# TM4C123GH6PM register map
Vendor: Texas Instruments; Series: TM4C; File version: 11073
CPU: CM4 r1p2, little endian, MPU, FPU, 3 interrupt priority bits
Registers are 32-bit, read-write, reset 0x1 unless marked. A register's access mark holds for its fields unless they carry their own. Offsets are from the block's base; [hi:lo] are bit positions.

## I2C0 — Register map for I2C0 peripheral
Base 0x40020000; register names take the prefix I2C0
Same registers: I2C1 0x40021000 (register names take the prefix I2C1), I2C2 0x40022000 (register names take the prefix I2C2), I2C3 0x40023000 (register names take the prefix I2C3)
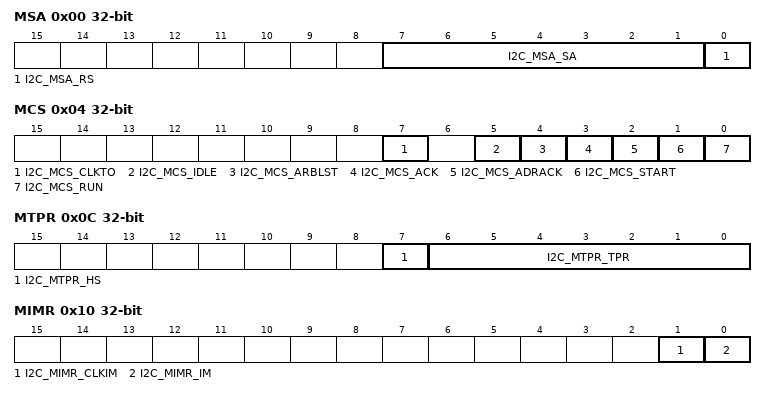
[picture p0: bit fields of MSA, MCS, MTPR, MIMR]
0x00 MSA (reset mask 0x0) — I2C Master Slave Address
  [7:1] I2C_MSA_SA — I2C Slave Address
  [0] I2C_MSA_RS — Receive not send
0x04 MCS (reset mask 0x0) — I2C Master Control/Status
  [7] I2C_MCS_CLKTO — Clock Timeout Error
  [5] I2C_MCS_IDLE — I2C Idle
  [4] I2C_MCS_ARBLST — Arbitration Lost
  [3] I2C_MCS_ACK — Data Acknowledge Enable
  [2] I2C_MCS_ADRACK — Acknowledge Address
  [1] I2C_MCS_START — Generate START
  [0] I2C_MCS_RUN — I2C Master Enable
0x04 MCS (reset mask 0x0) (I2C0_ALT view) — I2C Master Control/Status
  [6] I2C_MCS_BUSBSY — Bus Busy
  [4] I2C_MCS_HS — High-Speed Enable
  [3] I2C_MCS_DATACK — Acknowledge Data
  [2] I2C_MCS_STOP — Generate STOP
  [1] I2C_MCS_ERROR — Error
  [0] I2C_MCS_BUSY — I2C Busy
0x08 MDR (reset mask 0x0) — I2C Master Data
  [7:0] I2C_MDR_DATA — Data Transferred
0x0C MTPR (reset mask 0x0) — I2C Master Timer Period
  [7] I2C_MTPR_HS — High-Speed Enable
  [6:0] I2C_MTPR_TPR — Timer Period
0x10 MIMR (reset mask 0x0) — I2C Master Interrupt Mask
  [1] I2C_MIMR_CLKIM — Clock Timeout Interrupt Mask
  [0] I2C_MIMR_IM — Master Interrupt Mask
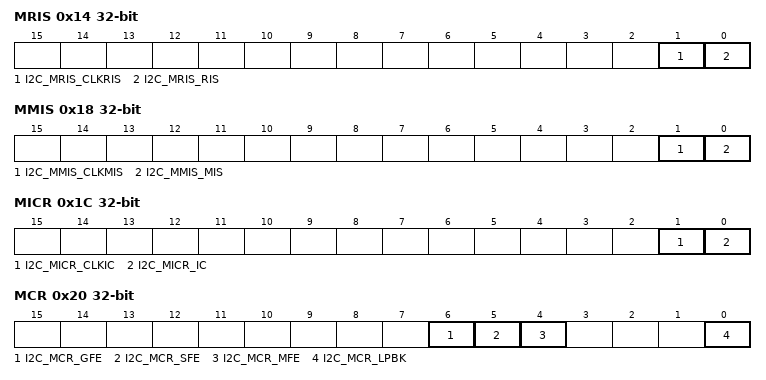
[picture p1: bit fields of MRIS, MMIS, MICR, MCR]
0x14 MRIS (reset mask 0x0) — I2C Master Raw Interrupt Status
  [1] I2C_MRIS_CLKRIS — Clock Timeout Raw Interrupt Status
  [0] I2C_MRIS_RIS — Master Raw Interrupt Status
0x18 MMIS (reset mask 0x0) — I2C Master Masked Interrupt Status
  [1] I2C_MMIS_CLKMIS — Clock Timeout Masked Interrupt Status
  [0] I2C_MMIS_MIS — Masked Interrupt Status
0x1C MICR wo (reset mask 0x0) — I2C Master Interrupt Clear
  [1] I2C_MICR_CLKIC — Clock Timeout Interrupt Clear
  [0] I2C_MICR_IC — Master Interrupt Clear
0x20 MCR (reset mask 0x0) — I2C Master Configuration
  [6] I2C_MCR_GFE — I2C Glitch Filter Enable
  [5] I2C_MCR_SFE — I2C Slave Function Enable
  [4] I2C_MCR_MFE — I2C Master Function Enable
  [0] I2C_MCR_LPBK — I2C Loopback
0x24 MCLKOCNT (reset mask 0x0) — I2C Master Clock Low Timeout Count
  [7:0] I2C_MCLKOCNT_CNTL — I2C Master Count
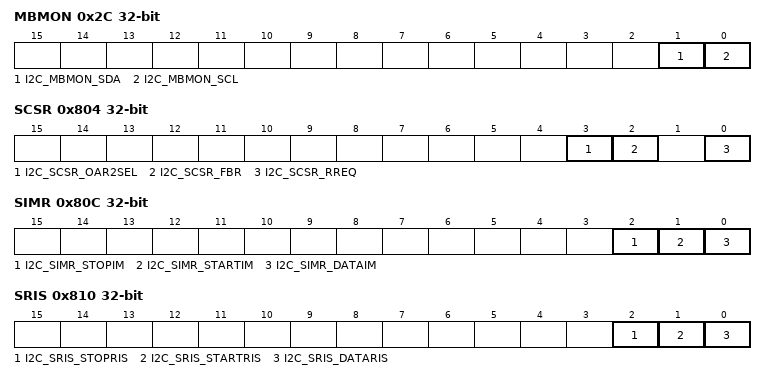
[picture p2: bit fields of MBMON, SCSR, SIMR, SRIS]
0x2C MBMON (reset mask 0x0) — I2C Master Bus Monitor
  [1] I2C_MBMON_SDA — I2C SDA Status
  [0] I2C_MBMON_SCL — I2C SCL Status
0x38 MCR2 (reset mask 0x0) — I2C Master Configuration 2
  [6:4] I2C_MCR2_GFPW — I2C Glitch Filter Pulse Width
    0=I2C_MCR2_GFPW_BYPASS (Bypass); 1=1 clock; 2=2 clocks; 3=3 clocks; 4=4 clocks; 5=8 clocks; 6=16 clocks; 7=32 clocks
0x800 SOAR (reset mask 0x0) — I2C Slave Own Address
  [6:0] I2C_SOAR_OAR
0x804 SCSR (reset mask 0x0) — I2C Slave Control/Status
  [3] I2C_SCSR_OAR2SEL — OAR2 Address Matched
  [2] I2C_SCSR_FBR — First Byte Received
  [0] I2C_SCSR_RREQ — Receive Request
0x804 SCSR (reset mask 0x0) (I2C0_ALT view) — I2C Slave Control/Status
  [1] I2C_SCSR_TREQ — Transmit Request
  [0] I2C_SCSR_DA — Device Active
0x808 SDR (reset mask 0x0) — I2C Slave Data
  [7:0] I2C_SDR_DATA — Data for Transfer
0x80C SIMR (reset mask 0x0) — I2C Slave Interrupt Mask
  [2] I2C_SIMR_STOPIM — Stop Condition Interrupt Mask
  [1] I2C_SIMR_STARTIM — Start Condition Interrupt Mask
  [0] I2C_SIMR_DATAIM — Data Interrupt Mask
0x810 SRIS (reset mask 0x0) — I2C Slave Raw Interrupt Status
  [2] I2C_SRIS_STOPRIS — Stop Condition Raw Interrupt Status
  [1] I2C_SRIS_STARTRIS — Start Condition Raw Interrupt Status
  [0] I2C_SRIS_DATARIS — Data Raw Interrupt Status
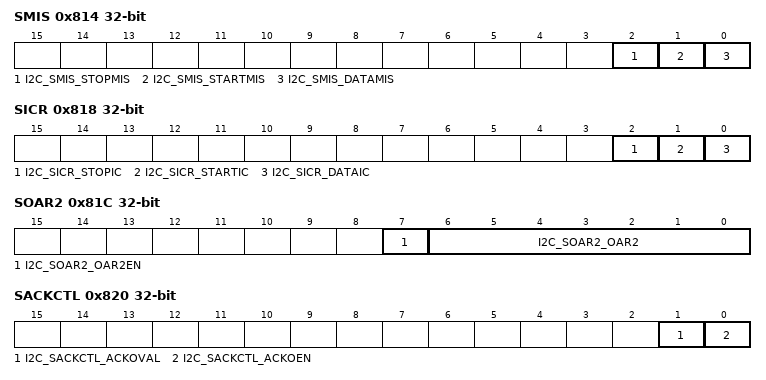
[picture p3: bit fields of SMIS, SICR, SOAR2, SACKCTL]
0x814 SMIS (reset mask 0x0) — I2C Slave Masked Interrupt Status
  [2] I2C_SMIS_STOPMIS — Stop Condition Masked Interrupt Status
  [1] I2C_SMIS_STARTMIS — Start Condition Masked Interrupt Status
  [0] I2C_SMIS_DATAMIS — Data Masked Interrupt Status
0x818 SICR wo (reset mask 0x0) — I2C Slave Interrupt Clear
  [2] I2C_SICR_STOPIC — Stop Condition Interrupt Clear
  [1] I2C_SICR_STARTIC — Start Condition Interrupt Clear
  [0] I2C_SICR_DATAIC — Data Interrupt Clear
0x81C SOAR2 (reset mask 0x0) — I2C Slave Own Address 2
  [7] I2C_SOAR2_OAR2EN — I2C Slave Own Address 2 Enable
  [6:0] I2C_SOAR2_OAR2 — I2C Slave Own Address 2
0x820 SACKCTL (reset mask 0x0) — I2C Slave ACK Control
  [1] I2C_SACKCTL_ACKOVAL — I2C Slave ACK Override Value
  [0] I2C_SACKCTL_ACKOEN — I2C Slave ACK Override Enable
0xFC0 PP (reset mask 0x0) — I2C Peripheral Properties
  [0] I2C_PP_HS — High-Speed Capable
0xFC4 PC (reset mask 0x0) — I2C Peripheral Configuration
  [0] I2C_PC_HS — High-Speed Capable
